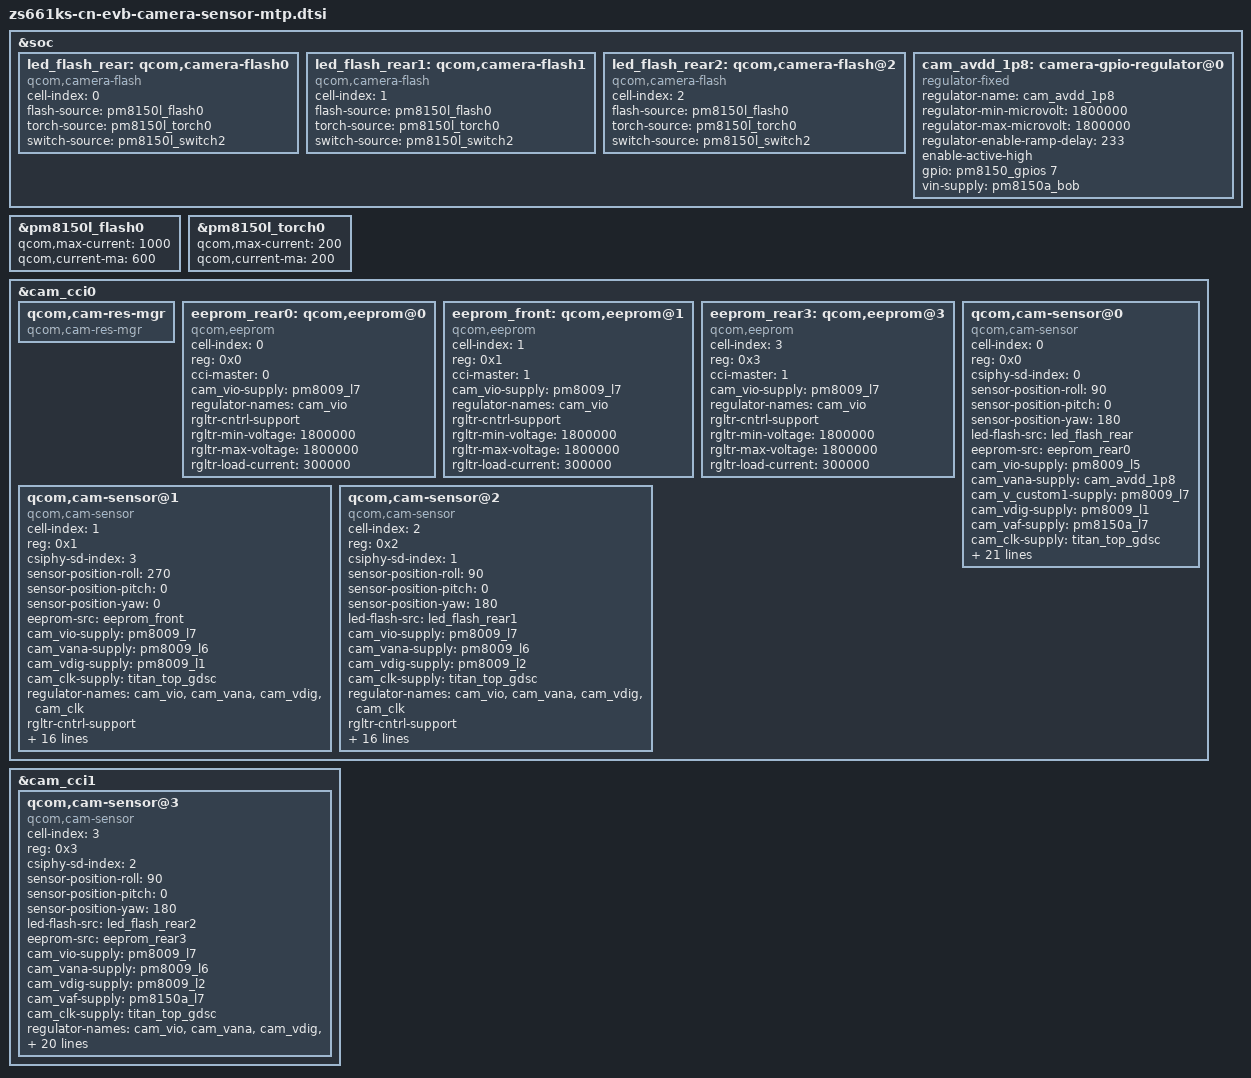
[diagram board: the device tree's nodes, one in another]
&soc {
	led_flash_rear: qcom,camera-flash0 {
		cell-index = <0>;
		compatible = "qcom,camera-flash";
		flash-source = <&pm8150l_flash0>;
		torch-source = <&pm8150l_torch0>;
		switch-source = <&pm8150l_switch2>;
		status = "ok";
	};

	led_flash_rear1: qcom,camera-flash1 {
		cell-index = <1>;
		compatible = "qcom,camera-flash";
		flash-source = <&pm8150l_flash0>;
		torch-source = <&pm8150l_torch0>;
		switch-source = <&pm8150l_switch2>;
		status = "ok";
	};

	led_flash_rear2: qcom,camera-flash@2 {
		cell-index = <2>;
		compatible = "qcom,camera-flash";
		flash-source = <&pm8150l_flash0>;
		torch-source = <&pm8150l_torch0>;
		switch-source = <&pm8150l_switch2>;
		status = "ok";
	};

	//AVDD  CAM_AVDD_1P8  IMX686
	cam_avdd_1p8: camera-gpio-regulator@0 {
		compatible = "regulator-fixed";
		regulator-name = "cam_avdd_1p8";
		regulator-min-microvolt = <1800000>;
		regulator-max-microvolt = <1800000>;
		regulator-enable-ramp-delay = <233>;
		enable-active-high;
		gpio = <&pm8150_gpios 7 0>;
		vin-supply = <&pm8150a_bob>;
	};

};
	&pm8150l_flash0 {
		qcom,max-current = <1000>;
		qcom,current-ma = <600>;
	};

	&pm8150l_torch0 {
		qcom,max-current = <200>;
		qcom,current-ma = <200>;
	};

&cam_cci0 {
	qcom,cam-res-mgr {
		compatible = "qcom,cam-res-mgr";
		status = "ok";
	};

	eeprom_rear0: qcom,eeprom@0 {
		cell-index = <0>;
		reg = <0x0>;
		cci-master = <0>;
		compatible = "qcom,eeprom";
		cam_vio-supply = <&pm8009_l7>;    //MCAM0_DOVDD_T_1P8
		regulator-names = "cam_vio";
		rgltr-cntrl-support;
		rgltr-min-voltage = <1800000>;
		rgltr-max-voltage = <1800000>;
		rgltr-load-current = <300000>;
		status = "ok";
	};

	eeprom_front: qcom,eeprom@1{
		cell-index = <1>;
		reg = <0x1>;
		cci-master = <1>;
		compatible = "qcom,eeprom";
		cam_vio-supply = <&pm8009_l7>;
		regulator-names = "cam_vio";
		rgltr-cntrl-support;
		rgltr-min-voltage = <1800000>;
		rgltr-max-voltage = <1800000>;
		rgltr-load-current = <300000>;
		status = "ok";
	};
	eeprom_rear3: qcom,eeprom@3{
		cell-index = <3>;
		reg = <0x3>;
		cci-master = <1>;
		compatible = "qcom,eeprom";
		cam_vio-supply = <&pm8009_l7>;
		regulator-names = "cam_vio";
		rgltr-cntrl-support;
		rgltr-min-voltage = <1800000>;
		rgltr-max-voltage = <1800000>;
		rgltr-load-current = <300000>;
		status = "ok";
	};
	//######## IMX686 #########
	qcom,cam-sensor@0 {
			cell-index = <0>;
			compatible = "qcom,cam-sensor";
			reg = <0x0>;
			csiphy-sd-index = <0>;
			sensor-position-roll = <90>;
			sensor-position-pitch = <0>;
			sensor-position-yaw = <180>;
			led-flash-src = <&led_flash_rear>;
			//actuator-src = <&actuator_rear1>;
			eeprom-src = <&eeprom_rear0>;
			cam_vio-supply = <&pm8009_l5>;          //CAM_AVDD1_2P9
			cam_vana-supply = <&cam_avdd_1p8>;      //CAM_AVDD_1P8
			cam_v_custom1-supply = <&pm8009_l7>;    //MCAM0_DOVDD_T_1P8
			cam_vdig-supply = <&pm8009_l1>;         //MCAM0_DVDD_T_1P1
			cam_vaf-supply = <&pm8150a_l7>;          //MVCM_2P8
			cam_clk-supply = <&titan_top_gdsc>;
			regulator-names = "cam_vio", "cam_vana", "cam_v_custom1", "cam_vdig", "cam_vaf", "cam_clk";
			rgltr-cntrl-support;
			rgltr-min-voltage = <2900000 1800000 1800000 1104000 2856000 0>;
			rgltr-max-voltage = <2900000 1800000 1800000 1104000 2856000 0>;
			rgltr-load-current = <0 80000 80000 0 0 0>;
			gpio-no-mux = <0>;
			pinctrl-names = "cam_default", "cam_suspend";
			pinctrl-0 = <&cam_sensor_mclk0_active>;
			pinctrl-1 = <&cam_sensor_mclk0_suspend>;
			gpios = <&tlmm 94 0>,
				<&tlmm 93 0>;
			gpio-reset = <1>;
			gpio-req-tbl-num = <0 1>;
			gpio-req-tbl-flags = <1 0>;
			gpio-req-tbl-label = "CAMIF_MCLK0",
						"CAM_RESET0";
			sensor-mode = <0>;
			cci-master = <0>;
			status = "ok";
			clocks = <&clock_camcc CAM_CC_MCLK0_CLK>;
			clock-names = "cam_clk";
			clock-cntl-level = "turbo";
			clock-rates = <19200000>;
		};


	//########### Front OV24B1Q 24M ###########
	qcom,cam-sensor@1 {
		cell-index = <1>;
		compatible = "qcom,cam-sensor";
		reg = <0x1>;
		csiphy-sd-index = <3>;
		sensor-position-roll = <270>;
		sensor-position-pitch = <0>;
		sensor-position-yaw = <0>;
		//led-flash-src = <&led_flash_front>;
		//actuator-src = <&actuator_rear1>;
		eeprom-src = <&eeprom_front>;
		cam_vio-supply = <&pm8009_l7>;			//CAM_DOVDD_F_1P8
		cam_vana-supply = <&pm8009_l6>;			//CAM_AVDD_F_2P8
		cam_vdig-supply = <&pm8009_l1>;			//MCAM0_DVDD_T1_1P1
		cam_clk-supply = <&titan_top_gdsc>;
		regulator-names = "cam_vio", "cam_vana", "cam_vdig", "cam_clk";
		rgltr-cntrl-support;
		rgltr-min-voltage = <1800000 2800000 1104000 0>;
		rgltr-max-voltage = <1800000 2800000 1104000 0>;
		rgltr-load-current = <0 80000 1200000 0 >;
		gpio-no-mux = <0>;
		pinctrl-names = "cam_default", "cam_suspend";
		pinctrl-0 = <&cam_sensor_mclk3_active>;
		pinctrl-1 = <&cam_sensor_mclk3_suspend>;
		gpios = <&tlmm 97 0>,
			<&tlmm 78 0>;
		gpio-reset = <1>;
		gpio-req-tbl-num = <0 1>;
		gpio-req-tbl-flags = <1 0>;
		gpio-req-tbl-label = "CAMIF_MCLK3",
					"CAM_RESET3";
		sensor-mode = <0>;
		cci-master = <1>;
		status = "ok";
		clocks = <&clock_camcc CAM_CC_MCLK3_CLK>;
		clock-names = "cam_clk";
		clock-cntl-level = "turbo";
		clock-rates = <19200000>;
	};

	//######## OV13855 #########
	qcom,cam-sensor@2 {
		cell-index = <2>;
		compatible = "qcom,cam-sensor";
		reg = <0x2>;
		csiphy-sd-index = <1>;
		sensor-position-roll = <90>;
		sensor-position-pitch = <0>;
		sensor-position-yaw = <180>;
		led-flash-src = <&led_flash_rear1>;
		//eeprom-src = <&eeprom_rear2>;
		cam_vio-supply = <&pm8009_l7>;      //MCAM1_DOVDD_W_1P8
		cam_vana-supply = <&pm8009_l6>;     //CAM_AVDD_2P8
		cam_vdig-supply = <&pm8009_l2>;     //MCAM1_DVDD_W_1P2
		cam_clk-supply = <&titan_top_gdsc>;
		regulator-names = "cam_vio", "cam_vana", "cam_vdig",
			"cam_clk";
		rgltr-cntrl-support;
		rgltr-min-voltage = <1800000 2800000 1200000 0>;
		rgltr-max-voltage = <1800000 2800000 1200000 0>;
		rgltr-load-current = <0 80000 1200000 0>;
		gpio-no-mux = <0>;
		pinctrl-names = "cam_default", "cam_suspend";
		pinctrl-0 = <&cam_sensor_mclk1_active>;
		pinctrl-1 = <&cam_sensor_mclk1_suspend>;
		gpios = <&tlmm 95 0>,
			<&tlmm 92 0>;
		gpio-reset = <1>;
		gpio-req-tbl-num = <0 1>;
		gpio-req-tbl-flags = <1 0>;
		gpio-req-tbl-label = "CAMIF_MCLK1",
					"CAM_RESET1";
		sensor-mode = <0>;
		cci-master = <1>;
		status = "ok";
		clocks = <&clock_camcc CAM_CC_MCLK1_CLK>;
		clock-names = "cam_clk";
		clock-cntl-level = "turbo";
		clock-rates = <19200000>;
	};
};


&cam_cci1 {

	//	########### Rear OV8856  8M AF ###########
	qcom,cam-sensor@3 {
		cell-index = <3>;
		compatible = "qcom,cam-sensor";
		reg = <0x3>;
		csiphy-sd-index = <2>;
		sensor-position-roll = <90>;
		sensor-position-pitch = <0>;
		sensor-position-yaw = <180>;
		led-flash-src = <&led_flash_rear2>;
		eeprom-src = <&eeprom_rear3>;
		cam_vio-supply = <&pm8009_l7>;			//CAM_DOVDD_AF_1P8
		cam_vana-supply = <&pm8009_l6>;			//CAM_AVDD_AF_2P8
		cam_vdig-supply = <&pm8009_l2>;			//CAM_DVDD_AF_1P2
		cam_vaf-supply = <&pm8150a_l7>;			//CAM_MVCM_AF_2P8
		cam_clk-supply = <&titan_top_gdsc>;
		regulator-names = "cam_vio", "cam_vana", "cam_vdig", "cam_vaf", "cam_clk";
		rgltr-cntrl-support;
		rgltr-min-voltage = <1800000 2800000 1200000 2856000 0>;
		rgltr-max-voltage = <1800000 2800000 1200000 2856000 0>;
		rgltr-load-current = <0 80000 1200000 0 0 >;
		gpio-no-mux = <0>;
		pinctrl-names = "cam_default", "cam_suspend";
		pinctrl-0 = <&cam_sensor_mclk2_active>;
		pinctrl-1 = <&cam_sensor_mclk2_suspend>;
		gpios = <&tlmm 96 0>,
			<&tlmm 109 0>;
		gpio-reset = <1>;
		gpio-req-tbl-num = <0 1>;
		gpio-req-tbl-flags = <1 0>;
		gpio-req-tbl-label = "CAMIF_MCLK2",
					"CAM_RESET2";
		sensor-mode = <0>;
		cci-master = <0>;
		status = "ok";
		clocks = <&clock_camcc CAM_CC_MCLK2_CLK>;
		clock-names = "cam_clk";
		clock-cntl-level = "turbo";
		clock-rates = <19200000>;
	};

};

